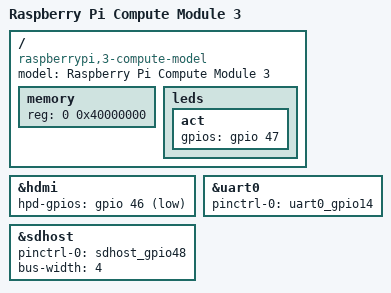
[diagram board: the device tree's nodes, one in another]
// SPDX-License-Identifier: GPL-2.0
/dts-v1/;
#include "bcm2837.dtsi"
#include "bcm2835-rpi.dtsi"
#include "bcm283x-rpi-usb-host.dtsi"

/ {
	compatible = "raspberrypi,3-compute-model", "brcm,bcm2837";
	model = "Raspberry Pi Compute Module 3";

	memory {
		reg = <0 0x40000000>;
	};

	leds {
		act {
			gpios = <&gpio 47 0>;
		};
	};
};

&hdmi {
	hpd-gpios = <&gpio 46 GPIO_ACTIVE_LOW>;
};

&uart0 {
	pinctrl-names = "default";
	pinctrl-0 = <&uart0_gpio14>;
	status = "okay";
};

/* SDHOST is used to drive the SD card */
&sdhost {
	pinctrl-names = "default";
	pinctrl-0 = <&sdhost_gpio48>;
	status = "okay";
	bus-width = <4>;
};
